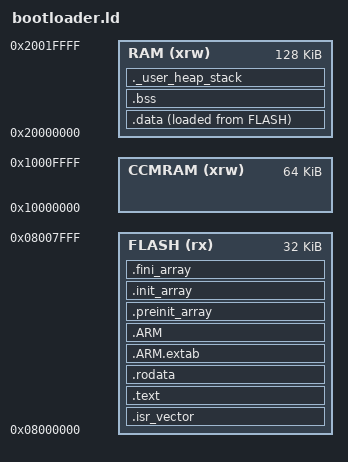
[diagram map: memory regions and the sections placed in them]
/*
******************************************************************************
**  Linker script for STM32F407 Bootloader
**  Bootloader sits at 0x08000000, size 32KB
******************************************************************************
*/

ENTRY(Reset_Handler)

MEMORY
{
RAM (xrw)      : ORIGIN = 0x20000000, LENGTH = 128K
CCMRAM (xrw)   : ORIGIN = 0x10000000, LENGTH = 64K
FLASH (rx)     : ORIGIN = 0x08000000, LENGTH = 32K
}

__bootloader_start__ = 0x08000000;
__bootloader_end__   = 0x08007FFF;
__app_start__        = 0x08008000;
__app_end__          = 0x0803FFFF;
__download_start__   = 0x08040000;
__download_end__     = 0x0807BFFF;
__config_start__     = 0x0807C000;
__config_end__       = 0x0807FFFF;

_estack = ORIGIN(RAM) + LENGTH(RAM);
_sstack = _estack - _Min_Stack_Size;
_Min_Heap_Size = 0x100;
_Min_Stack_Size = 0x200;

SECTIONS
{
  .isr_vector :
  {
    . = ALIGN(4);
    KEEP(*(.isr_vector))
    . = ALIGN(4);
  } >FLASH

  .text :
  {
    . = ALIGN(4);
    *(.text) *(.text*) *(.glue_7) *(.glue_7t) *(.eh_frame)
    KEEP (*(.init)) KEEP (*(.fini))
    . = ALIGN(4);
    _etext = .;
  } >FLASH

  .rodata :
  {
    . = ALIGN(4);
    *(.rodata) *(.rodata*)
    . = ALIGN(4);
  } >FLASH

  .ARM.extab (READONLY) :
  {
    . = ALIGN(4);
    *(.ARM.extab* .gnu.linkonce.armextab.*)
    . = ALIGN(4);
  } >FLASH

  .ARM (READONLY) :
  {
    . = ALIGN(4);
    __exidx_start = .;
    *(.ARM.exidx*)
    __exidx_end = .;
    . = ALIGN(4);
  } >FLASH

  .preinit_array (READONLY) :
  {
    . = ALIGN(4);
    PROVIDE_HIDDEN (__preinit_array_start = .);
    KEEP (*(.preinit_array*))
    PROVIDE_HIDDEN (__preinit_array_end = .);
    . = ALIGN(4);
  } >FLASH

  .init_array (READONLY) :
  {
    . = ALIGN(4);
    PROVIDE_HIDDEN (__init_array_start = .);
    KEEP (*(SORT(.init_array.*))) KEEP (*(.init_array*))
    PROVIDE_HIDDEN (__init_array_end = .);
    . = ALIGN(4);
  } >FLASH

  .fini_array (READONLY) :
  {
    . = ALIGN(4);
    PROVIDE_HIDDEN (__fini_array_start = .);
    KEEP (*(SORT(.fini_array.*))) KEEP (*(.fini_array*))
    PROVIDE_HIDDEN (__fini_array_end = .);
    . = ALIGN(4);
  } >FLASH

  _sidata = LOADADDR(.data);

  .data :
  {
    . = ALIGN(4);
    _sdata = .;
    *(.data) *(.data*) *(.RamFunc) *(.RamFunc*)
    . = ALIGN(4);
    _edata = .;
  } >RAM AT> FLASH

  .bss (NOLOAD) : ALIGN(4)
  {
    _sbss = .;
    __bss_start__ = _sbss;
    *(.bss) *(.bss*) *(COMMON)
    . = ALIGN(4);
    _ebss = .;
    __bss_end__ = _ebss;
  } >RAM

  ._user_heap_stack (NOLOAD) :
  {
    . = ALIGN(8);
    PROVIDE ( end = . );
    PROVIDE ( _end = . );
    . = . + _Min_Heap_Size;
    . = . + _Min_Stack_Size;
    . = ALIGN(8);
  } >RAM

  /DISCARD/ :
  {
    libc.a:* ( * )
    libm.a:* ( * )
    libgcc.a:* ( * )
  }
}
